# RZN2H register map
Vendor: Renesas Electronics Corporation; Series: RZN; File version: 1.00.00
CPU: other r0p0, little endian, MPU, no FPU, VTOR, 4 interrupt priority bits, 624 interrupts
Registers are 32-bit, read-write, reset 0x0 unless marked. A register's access mark holds for its fields unless they carry their own. Offsets are from the block's base; [hi:lo] are bit positions; {n}, {i} and the like mark numbered series; 'fields as' and 'values as' point back to an identical list.

## SCI0 — Serial Communication Interface 0
Base 0x80005000
Same registers: SCI1 0x80005400, SCI2 0x80005800, SCI3 0x80005C00, SCI4 0x80006000, SCI5 0x81005000, SCIE{n} {0x90030000+0x400*n} (n=0..7), SCIE8 0x90130000, SCIE9 0x90130400, SCIE10 0x90130800, SCIE11 0x90130C00
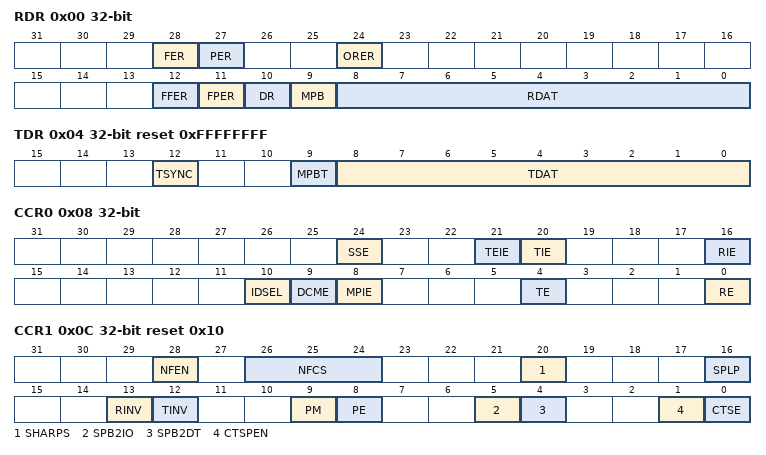
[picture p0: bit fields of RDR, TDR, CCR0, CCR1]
0x00 RDR ro — Receive Data Register
  [28] FER — Framing error flag
  [27] PER — Parity error flag
  [24] ORER — Overrun Error flag
  [12] FFER — FIFO framing error flag
    0=There is no framing error in the data read from the receive FIFO; 1=There is framing error in the data read from the receive FIFO
  [11] FPER — FIFO parity error flag
    0=There is no parity error in the data read from the receive FIFO; 1=There is parity error in the data read from the receive FIFO
  [10] DR — Receive data ready flag
  [9] MPB — Multi-processor flag
    0=Data transmission cycles; 1=ID transmission cycles
  [8:0] RDAT — Serial receive data
0x04 TDR reset 0xFFFFFFFF — Transmit Data Register
  [12] TSYNC — Transmit SYNC Data Bit
    0=The Start Bit is transmitted as DATA SYNC; 1=The Start Bit is transmitted as COMMAND SYNC
  [9] MPBT — Multi-processor transfer bit flag
    0=Data transmission cycles; 1=ID transmission cycles
  [8:0] TDAT — Serial transmit data
0x08 CCR0 — Common Control Register 0
  [24] SSE — SSn# Pin Function Enable
    0=SSn# pin function is disabled; 1=SSn# pin function is enabled
  [21] TEIE — Transmit End Interrupt Enable
    0=TEI interrupt request is disabled; 1=TEI interrupt request is enabled
  [20] TIE — Transmit Interrupt Enable
    0=TXI interrupt request is disabled; 1=TXI interrupt request is enabled
  [16] RIE — Receive Interrupt Enable
    0=RXI and ERI interrupt requests are disabled; 1=RXI and ERI interrupt requests are enabled
  [10] IDSEL — ID frame select
    0=All data is to be compared; 1=The data with RDR.MPB = 1 is to be compared
  [9] DCME — Data Compare Match Enable
    0=Address match function is disabled; 1=Address match function is enabled
  [8] MPIE — Multi-Processor Interrupt Enable
    0=Non-Multi-Processor reception; 1=Multi-Processor reception
  [4] TE — Transmit Enable
    0=Serial transmission is disabled; 1=Serial transmission is enabled
  [0] RE — Receive Enable
    0=Serial reception is disabled; 1=Serial reception is enabled
0x0C CCR1 reset 0x10 — Common Control Register 1
  [28] NFEN — Digital Noise Filter Function Enable
    0=Noise filter disabled; 1=Noise filter enabled
  [26:24] NFCS — Noise Filter Clock Select
    0=The base clock signal divided by 1; 1=The baud rate generator source clock divided by 1; 2=The baud rate generator source clock divided by 2; 3=The baud rate generator source clock divided by 4; 4=The baud rate generator source clock divided by 8; other=Others (Setting prohibited)
  [20] SHARPS — Half-duplex communication select
    0=The TXD pin and the RXD pin independent; 1=Half-duplex communication using TXD pin
  [16] SPLP — Loopback Control
    0=Normal mode; 1=Loopback mode
  [13] RINV — RXD invert
    0=Received data from RXD is not inverted and input; 1=Received data from RXD is inverted and input
  [12] TINV — TXD invert
    0=Transmit data is not inverted and output to TXD; 1=Transmit data is inverted and output to TXD
  [9] PM — Parity Mode
    0=Selects even parity; 1=Selects odd parity
  [8] PE — Parity Enable
    0=Parity bit addition is not performed, when transmitting. Parity bit checking is not performed, when receiving.; 1=The parity bit is added, when transmitting. The parity bit is checked, when receiving.
  [5] SPB2IO — Serial port break I/O
    0=The value of SPB2DT bit is not output in TXD pin; 1=The value of SPB2DT bit is output in TXD pin
  [4] SPB2DT — Serial port break data select
    0=Low level is output in TXD pin, when TINV = 0. High level is output in TXD pin, when TINV = 1.; 1=High level is output in TXD pin, when TINV = 0. Low level is output in TXD pin, when TINV = 1.
  [1] CTSPEN — CTS external pin Enable
    0=1-pin mode, CTS and RTS share 1 pin; 1=2-pin mode, CTS and RTS have dedicated pins
  [0] CTSE — CTS Enable
    0=CTS function is disabled (RTS output function is enabled); 1=CTS function is enabled
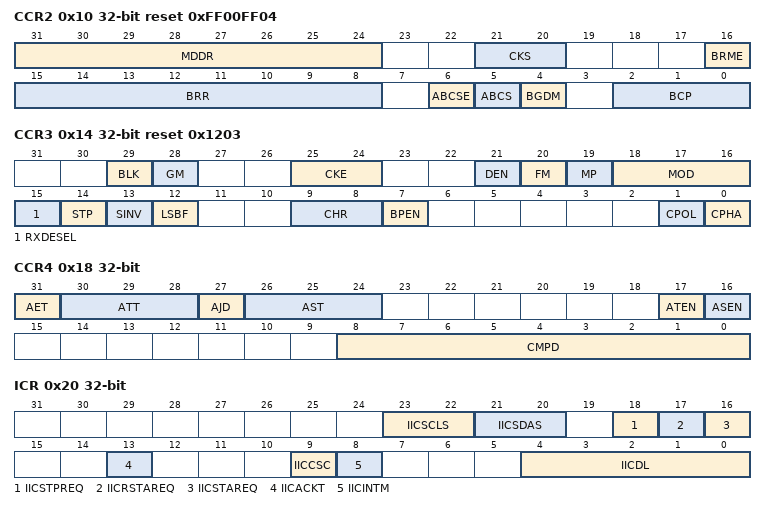
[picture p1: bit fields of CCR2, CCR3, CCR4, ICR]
0x10 CCR2 reset 0xFF00FF04 — Common Control Register 2
  [31:24] MDDR — Modulation Duty setting
  [21:20] CKS — Clock Select
    0=PCLKSCIn clock (n = 0); 1=PCLKSCIn/4 clock (n = 1); 2=PCLKSCIn/16 clock (n = 2); 3=PCLKSCIn/64 clock (n = 3)
  [16] BRME
    0=Bit rate modulation function is disabled; 1=Bit rate modulation function is enabled
  [15:8] BRR — Bit rate setting
  [6] ABCSE — Asynchronous Mode Extended Base Clock Select
    0=Clock cycles for 1-bit period are decided with combination between CCR2.BGDM and CCR2.ABCS; 1=6 base clock cycles for 1-bit period and doubled frequency is output from the baud rate generator
  [5] ABCS — Asynchronous Mode Base Clock Select
    0=Selects 16 base clock cycles for 1-bit period; 1=Selects 8 base clock cycles for 1-bit period
  [4] BGDM — Baud Rate Generator Double-Speed Mode Select
    0=Baud rate generator outputs the clock with single frequency; 1=Baud rate generator outputs the clock with doubled frequency
  [2:0] BCP — Base Clock Pulse
    0=93 clock cycles (S = 93); 1=128 clock cycles (S = 128); 2=186 clock cycles (S = 186); 3=512 clock cycles (S = 512); 4=32 clock cycles (S = 32) (Initial value); 5=64 clock cycles (S = 64); 6=372 clock cycles (S = 372); 7=256 clock cycles (S = 256)
0x14 CCR3 reset 0x1203 — Common Control Register 3
  [29] BLK — Block Transfer Mode
    0=Non-block transfer mode operation; 1=Block transfer mode operation
  [28] GM — GSM Mode
    0=Non-GSM mode operation; 1=GSM mode operation
  [25:24] CKE — Clock enable
  [21] DEN — Driver enable
    0=RS-485 Driver control function disable; 1=RS-485 Driver control function enable
  [20] FM — FIFO Mode select
    0=Non-FIFO mode (TDR and RDR registers are non-FIFO); 1=FIFO mode (TDR and RDR registers are FIFO)
  [19] MP — Multi-Processor Mode
    0=Multi-processor communications function is disabled; 1=Multi-processor communications function is enabled
  [18:16] MOD — Communication mode select
    0=Asynchronous mode (Multi-processor mode); 1=Smart card interface mode; 2=Clock synchronous mode; 3=Simple SPI mode; 4=Simple I2C mode; 5=Manchester mode; other=Others (Setting prohibited)
  [15] RXDESEL — Asynchronous Start Bit Edge Detection Select
    0=The low level on the RXDn pin is detected as the start bit; 1=A falling edge on the RXDn pin is detected as the start bit
  [14] STP — Stop Bit Length
    0=1 stop bit; 1=2 stop bits
  [13] SINV — Transmitted/Received Data Invert
    0=TDR contents are transmitted to TSR as they are. RSR contents are stored to RDR as they are.; 1=TDR contents are inverted before being transmitted to TSR. RSR contents are inverted and stored to RDR.
  [12] LSBF — LSB First select
    0=MSB first; 1=LSB first
  [9:8] CHR — Character Length
    0=Transmit/receive in 9-bit data length; 1=Transmit/receive in 9-bit data length; 2=Transmit/receive in 8-bit data length (initial value); 3=Transmit/receive in 7-bit data length
  [7] BPEN — Synchronizer bypass enable
    0=Synchronizer circuit is not bypassed; 1=Synchronizer circuit is bypassed
  [1] CPOL — Clock Polarity Select
    0=SCKn in idle state is 0; 1=SCKn in idle state is 1
  [0] CPHA — Clock Phase Select
    0=Data is sampled at an odd edge and changes at an even edge. (Clock is delayed.); 1=Data changes at an odd edge and is sampled at an even edge. (Clock is not delayed.)
0x18 CCR4 — Common Control Register 4
  [31] AET — Adjustment edge for transmit timing
    0=Adjust the rising edge timing, when CCR1.TINV = 0. Adjust the falling edge timing, when CCR1.TINV = 1.; 1=Adjust the falling edge timing, when CCR1.TINV = 0. Adjust the rising edge timing, when CCR1.TINV = 1.
  [30:28] ATT — Adjustment value for Transmit timing
  [27] AJD — Adjustment Direction for receive sampling timing
    0=The sampling timing is adjusted backward to the middle of bit; 1=The sampling timing is adjusted forward to the middle of bit
  [26:24] AST — Adjustment value for receive Sampling Timing
  [17] ATEN — Adjust transmit timing enable
    0=Adjust transmit timing disable; 1=Adjust transmit timing enable
  [16] ASEN — Adjust receive sampling timing enable
    0=Adjust sampling timing disable; 1=Adjust sampling timing enable
  [8:0] CMPD — Compare Match Data
0x20 ICR — Simple I2C Control Register
  [23:22] IICSCLS
    0=Serial clock output; 1=Generate a start, restart, or stop condition; 2=Output the low level on the SCLn pin; 3=Place the SCLn pin in the high-impedance state
  [21:20] IICSDAS
    0=Serial data output; 1=Generate a start, restart, or stop condition; 2=Output the low level on the SDAn pin; 3=Place the SDAn pin in the high-impedance state
  [18] IICSTPREQ
    0=A stop condition is not generated; 1=A stop condition is generated
  [17] IICRSTAREQ
    0=A restart condition is not generated; 1=A restart condition is generated
  [16] IICSTAREQ
    0=A start condition is not generated; 1=A start condition is generated
  [13] IICACKT
    0=ACK transmission; 1=NACK transmission and reception of ACK/NACK
  [9] IICCSC
    0=No synchronization with the clock signal; 1=Synchronization with the clock signal
  [8] IICINTM
    0=Use ACK/NACK interrupts; 1=Use reception and transmission interrupts
  [4:0] IICDL — SDA Delay Output Select
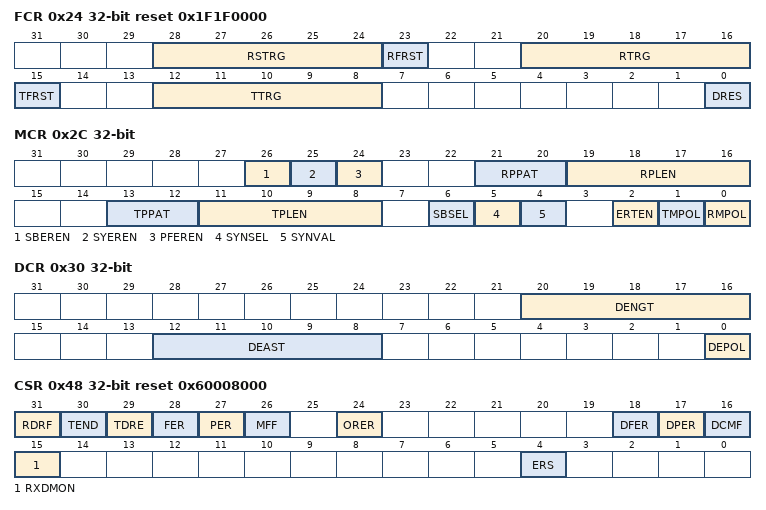
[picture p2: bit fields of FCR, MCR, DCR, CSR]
0x24 FCR reset 0x1F1F0000 — FIFO Control Register
  [28:24] RSTRG — RTS# Output Active Trigger Number Select
  [23] RFRST wo — Receive FIFO Data Register Reset
    0=It is invalid. It does not affect the operation.; 1=The number of data stored in receive FIFO (RDR register) are made 0
  [20:16] RTRG — Receive FIFO data trigger number
  [15] TFRST wo — Transmit FIFO Data Register Reset
    0=It is invalid. It does not affect the operation.; 1=The number of data stored in transmit FIFO (TDR register) are made 0
  [12:8] TTRG — Transmit FIFO data trigger number
  [0] DRES — Receive data ready error select
    0=reception data full interrupt (RXI); 1=receive error interrupt (ERI)
0x2C MCR — Manchester Control Register
  [26] SBEREN — Start Bit Error Enable
    0=Does not handle a start bit error as an interrupt source; 1=Handles a start bit error as an interrupt source
  [25] SYEREN — Receive SYNC Error Enable
    0=Does not handle a receive SYNC error as an interrupt source; 1=Handles a receive SYNC error as an interrupt source
  [24] PFEREN — Preface Error Enable
    0=Does not handle a preface error as an interrupt source; 1=Handles a preface error as an interrupt source
  [21:20] RPPAT — Receive Preface Pattern
    0=ALL ZERO; 1=ZERO ONE; 2=ONE ZERO; 3=ALL ONE
  [19:16] RPLEN — Receive Preface Length
    0=Disables the receive preface generation; other=Others (Receive preface length (bit length))
  [13:12] TPPAT — Transmit preface pattern
    0=ALL ZERO; 1=ZERO ONE; 2=ONE ZERO; 3=ALL ONE
  [11:8] TPLEN — Transmit preface length
    0=Disables the transmit preface generation; other=Others (Transmit preface length (bit length))
  [6] SBSEL
    0=The start bit area consists of one bit; 1=The start bit area consists of three bits. (COMMAND SYNC or DATA SYNC)
  [5] SYNSEL
    0=The start bit pattern is set with the SYNVAL bit; 1=The start bit pattern is set with the TSYNC bit
  [4] SYNVAL — SYNC value Setting
    0=The start bit is added as a zero-to-one transition; 1=The start bit is added as a one-to-zero transition
  [2] ERTEN — Manchester Edge Retiming Enable
    0=Disables the receive retiming function; 1=Enables the receive retiming function
  [1] TMPOL — Polarity of Transmit Manchester Code
    0=Logic 0 is coded as a zero-to-one transition in Manchester code Logic 1 is coded as a one-to-zero transition in Manchester code; 1=Logic 0 is coded as a one-to-zero transition in Manchester code Logic 1 is coded as a zero-to-one transition in Manchester code
  [0] RMPOL — Polarity of Received Manchester Code
    values as TMPOL
0x30 DCR — Driver Control Register
  [20:16] DENGT — Driver negate time
  [12:8] DEAST — Driver Assertion Time
  [0] DEPOL — Driver effective polarity select
    0=The DE signal is active high; 1=The DE signal is active low
0x48 CSR ro reset 0x60008000 — Common Status Register
  [31] RDRF
    0=No received data is in RDR register (Non-FIFO mode) The quantity of receive data written in receive FIFO falls below the specified receive triggering number (FIFO mode); 1=Received data is in RDR register (Non-FIFO mode) The quantity of receive data written in receive FIFO is equal to or greater than the specified receive triggering number (FIFO mode)
  [30] TEND
    0=A character is being transmitted or standing by for transmission; 1=Character transfer has been completed
  [29] TDRE — Transmit Data Empty Flag
    0=Transmit data is in TDR register (Non-FIFO mode) The quantity of transmit data written in transmit FIFO exceeds the specified transmit triggering number. (FIFO mode); 1=No transmit data is in TDR register (Non-FIFO mode) The quantity of transmit data written in transmit FIFO is equal to or less than the specified transmit triggering number. (FIFO mode)
  [28] FER
    0=No framing error occurred (Non-FIFO mode) No framing error in all received data in receive FIFO (FIFO mode); 1=A framing error has occurred (Non-FIFO mode) One or more framing errors occurred in received data in receive FIFO (FIFO mode)
  [27] PER
    0=No parity error occurred (Non-FIFO mode) No parity error in all received data in receive FIFO (FIFO mode); 1=A parity error has occurred (Non-FIFO mode) One or more parity errors occurred in received data in receive FIFO (FIFO mode)
  [26] MFF — Mode Fault Error Flag
    0=No mode fault error; 1=Mode fault error
  [24] ORER
    0=No overrun error occurred; 1=An overrun error has occurred
  [18] DFER — Data Compare Match Framing Error Flag
    0=No framing error occurred at address match detection; 1=A framing error has occurred at address match detection
  [17] DPER — Data Compare Match Parity Error Flag
    0=No parity error occurred at address match detection; 1=A parity error has occurred at address match detection
  [16] DCMF — Data Compare Match Flag
    0=No matched; 1=Matched
  [15] RXDMON — Serial input data monitor
    0=RXD pin is the Low level, when CCR1.RINV = 0. RXD pin is the High level, when CCR1.RINV = 1.; 1=RXD pin is the High level, when CCR1.RINV = 0. RXD pin is the Low level, when CCR1.RINV = 1.
  [4] ERS — Error Signal Status Flag
    0=Error signal Low not responded; 1=Error signal Low responded
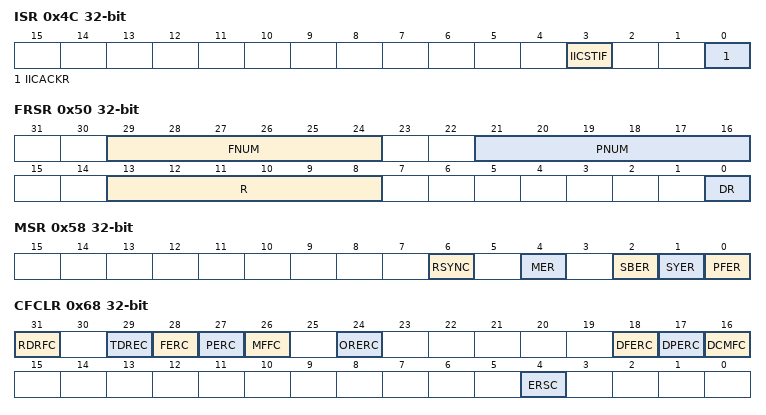
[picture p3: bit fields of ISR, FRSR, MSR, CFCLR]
0x4C ISR ro — Simple I2C Status Register
  [3] IICSTIF — Issuing of Start, Restart, or Stop Condition Completed Flag
    0=There are no requests for generating conditions or a condition is being generated; 1=A start, restart, or stop condition is completely generated
  [0] IICACKR — ACK Reception Data Flag
    0=ACK received; 1=NACK received
0x50 FRSR ro — FIFO Receive Status Register
  [29:24] FNUM — Framing Error Count
  [21:16] PNUM — Parity Error Count
  [13:8] R — Receive FIFO Data Count
  [0] DR
    0=Receiving is in progress, or no received data has remained in receive FIFO after normally completed receiving. (Receive FIFO is empty.); 1=The following receive data does not come for a fixed period after storing data below the threshold
0x54 FTSR ro — FIFO Transmit Status Register
  [5:0] T — Transmit FIFO Data Count
0x58 MSR ro — Manchester Status Register
  [6] RSYNC — Receive SYNC data bit
    0=The received the Start Bit is DATA SYNC; 1=The received the Start Bit is COMMAND SYNC
  [4] MER — Manchester Error Flag
    0=No Manchester error occurred; 1=Manchester error has occurred
  [2] SBER — Start Bit Error flag
    0=No start bit error detected; 1=Start bit error detected
  [1] SYER — SYNC Error flag
    0=No receive SYNC error detected; 1=Receive SYNC error detected
  [0] PFER — Preface Error flag
    0=No preface error detected; 1=Preface error detected
0x68 CFCLR wo — Common Flag Clear Register
  [31] RDRFC
    0=No effect; 1=Clear the CSR.RDRF bit
  [29] TDREC
    0=No effect; 1=Clear the CSR.TDRE bit
  [28] FERC
    0=No effect; 1=Clear the CSR.FER bit
  [27] PERC
    0=No effect; 1=Clear the CSR.PER bit
  [26] MFFC
    0=No effect; 1=Clear the CSR.MFF bit
  [24] ORERC
    0=No effect; 1=Clear the CSR.ORER bit
  [18] DFERC
    0=No effect; 1=Clear the CSR.DFER bit
  [17] DPERC
    0=No effect; 1=Clear the CSR.DPER bit
  [16] DCMFC
    0=No effect; 1=Clear the CSR.DCMF bit
  [4] ERSC
    0=No effect; 1=Clear the CSR.ERS bit
0x6C ICFCLR wo — Simple I2C Flag Clear Register
  [3] IICSTIFC
    0=No effect; 1=Clear the ISR.IICSTIF bit
0x70 FFCLR wo — FIFO Flag Clear Register
  [0] DRC
    0=No effect; 1=Clear the FRSR.DR bit
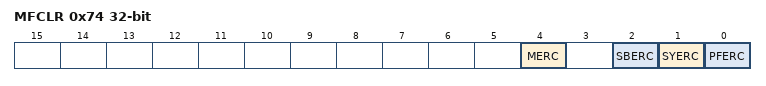
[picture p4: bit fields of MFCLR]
0x74 MFCLR wo — Manchester Flag Clear Register
  [4] MERC — MER clear bit
  [2] SBERC — SBER clear bit
  [1] SYERC — SYER clear bit
  [0] PFERC — PFER clear bit
